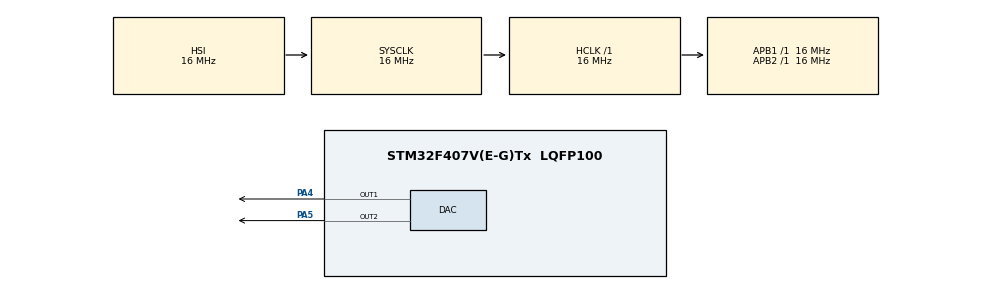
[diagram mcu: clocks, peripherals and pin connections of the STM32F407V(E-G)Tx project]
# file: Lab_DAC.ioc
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DAC.DAC_Trigger=DAC_TRIGGER_T6_TRGO
DAC.TriangleAmplitude=DAC_TRIANGLEAMPLITUDE_4095
DAC.WaveGeneration=TriangleWaveGeneration
Mcu.Family=STM32F4
Mcu.Name=STM32F407V(E-G)Tx
Mcu.Package=LQFP100
NVIC.PriorityGroup=NVIC_PRIORITYGROUP_4
PA13.Mode=Serial_Wire
PA13.Signal=SYS_JTMS-SWDIO
PA14.Mode=Serial_Wire
PA14.Signal=SYS_JTCK-SWCLK
PA4.Signal=COMP_DAC1_group
PA5.Signal=COMP_DAC2_group
ProjectManager.HeapSize=0x200
ProjectManager.StackSize=0x400
ProjectManager.TargetToolchain=MDK-ARM V5.32
RCC.AHBFreq_Value=16000000
RCC.APB1Freq_Value=16000000
RCC.APB2Freq_Value=16000000
RCC.CortexFreq_Value=16000000
RCC.HSE_VALUE=25000000
RCC.HSI_VALUE=16000000
RCC.LSE_VALUE=32768
RCC.SYSCLKFreq_VALUE=16000000
RCC.VCOOutputFreq_Value=192000000
SH.COMP_DAC1_group.0=DAC_OUT1,DAC_OUT1
SH.COMP_DAC2_group.0=DAC_OUT2,DAC_OUT2
TIM6.Period=1000-1
TIM6.Prescaler=16-1
TIM6.TIM_MasterOutputTrigger=TIM_TRGO_UPDATE
VP_TIM6_VS_ClockSourceINT.Mode=Enable_Timer
board=custom

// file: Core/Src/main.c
/* USER CODE BEGIN Header */
/**
  ******************************************************************************
  * @file           : main.c
  * @brief          : Main program body
  ******************************************************************************
  * @attention
  *
  * Copyright (c) 2024 STMicroelectronics.
  * All rights reserved.
  *
  * This software is licensed under terms that can be found in the LICENSE file
  * in the root directory of this software component.
  * If no LICENSE file comes with this software, it is provided AS-IS.
  *
  ******************************************************************************
  */
/* USER CODE END Header */
#include "main.h"
#include "dac.h"
#include "tim.h"
#include "gpio.h"

void SystemClock_Config(void);

int main(void)
{

  /* MCU Configuration--------------------------------------------------------*/

  /* Reset of all peripherals, Initializes the Flash interface and the Systick. */
  HAL_Init();

  /* Configure the system clock */
  SystemClock_Config();

  /* Initialize all configured peripherals */
  MX_GPIO_Init();
  MX_DAC_Init();
  MX_TIM6_Init();

  /* Infinite loop */
  /* USER CODE BEGIN WHILE */
  //HAL_DAC_SetValue(&hdac, DAC_CHANNEL_1, DAC_ALIGN_12B_R, 1024);
  HAL_DAC_Start(&hdac, DAC_CHANNEL_1);
  //HAL_DAC_Stop(&hdac, DAC_CHANNEL_1);
  HAL_TIM_Base_Start(&htim6);
  //HAL_DAC_SetValue(&hdac, DAC_CHANNEL_1, DAC_ALIGN_12B_R, 3000);
  HAL_DACEx_NoiseWaveGenerate(&hdac, DAC_CHANNEL_1, 3000);
  while (1)
  {
    /* USER CODE END WHILE */

  }
}

void SystemClock_Config(void)
{
  RCC_OscInitTypeDef RCC_OscInitStruct = {0};
  RCC_ClkInitTypeDef RCC_ClkInitStruct = {0};

  /** Configure the main internal regulator output voltage
  */
  __HAL_RCC_PWR_CLK_ENABLE();
  __HAL_PWR_VOLTAGESCALING_CONFIG(PWR_REGULATOR_VOLTAGE_SCALE1);

  /** Initializes the RCC Oscillators according to the specified parameters
  * in the RCC_OscInitTypeDef structure.
  */
  RCC_OscInitStruct.OscillatorType = RCC_OSCILLATORTYPE_HSI;
  RCC_OscInitStruct.HSIState = RCC_HSI_ON;
  RCC_OscInitStruct.HSICalibrationValue = RCC_HSICALIBRATION_DEFAULT;
  RCC_OscInitStruct.PLL.PLLState = RCC_PLL_NONE;
  if (HAL_RCC_OscConfig(&RCC_OscInitStruct) != HAL_OK)
  {
    Error_Handler();
  }

  /** Initializes the CPU, AHB and APB buses clocks
  */
  RCC_ClkInitStruct.ClockType = RCC_CLOCKTYPE_HCLK|RCC_CLOCKTYPE_SYSCLK
                              |RCC_CLOCKTYPE_PCLK1|RCC_CLOCKTYPE_PCLK2;
  RCC_ClkInitStruct.SYSCLKSource = RCC_SYSCLKSOURCE_HSI;
  RCC_ClkInitStruct.AHBCLKDivider = RCC_SYSCLK_DIV1;
  RCC_ClkInitStruct.APB1CLKDivider = RCC_HCLK_DIV1;
  RCC_ClkInitStruct.APB2CLKDivider = RCC_HCLK_DIV1;

  if (HAL_RCC_ClockConfig(&RCC_ClkInitStruct, FLASH_LATENCY_0) != HAL_OK)
  {
    Error_Handler();
  }
}

void Error_Handler(void)
{
  __disable_irq();
  while (1)
  {
  }
}
